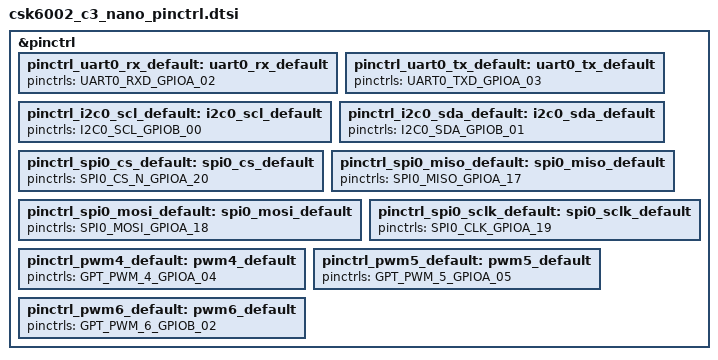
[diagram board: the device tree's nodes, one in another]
#include "csk/csk6_pinctrl.dtsi"

#define csk6002_c3_nano_pinctrl pinctrl \
        __PINCTRL_DEPRECATED__("This node has been deprecated," \
                "please use 'pinctrl' instead of 'csk6002_c3_nano_pinctrl")

&pinctrl {
        pinctrl_uart0_rx_default: uart0_rx_default{
                pinctrls = <UART0_RXD_GPIOA_02>;
        };

        pinctrl_uart0_tx_default: uart0_tx_default{
                pinctrls = <UART0_TXD_GPIOA_03>;
        };

        pinctrl_i2c0_scl_default: i2c0_scl_default{
                pinctrls = <I2C0_SCL_GPIOB_00>;
        };

        pinctrl_i2c0_sda_default: i2c0_sda_default{
                pinctrls = <I2C0_SDA_GPIOB_01>;
        };

        pinctrl_spi0_cs_default: spi0_cs_default{
                pinctrls = <SPI0_CS_N_GPIOA_20>;
        };

        pinctrl_spi0_miso_default: spi0_miso_default{
                pinctrls = <SPI0_MISO_GPIOA_17>;
        };

        pinctrl_spi0_mosi_default: spi0_mosi_default{
                pinctrls = <SPI0_MOSI_GPIOA_18>;
        };

        pinctrl_spi0_sclk_default: spi0_sclk_default{
                pinctrls = <SPI0_CLK_GPIOA_19>;
        };
        pinctrl_pwm4_default: pwm4_default{
                pinctrls = <GPT_PWM_4_GPIOA_04>;
        };

        pinctrl_pwm5_default: pwm5_default{
                pinctrls = <GPT_PWM_5_GPIOA_05>;
        };

        pinctrl_pwm6_default: pwm6_default{
                pinctrls = <GPT_PWM_6_GPIOB_02>;
        };
};
